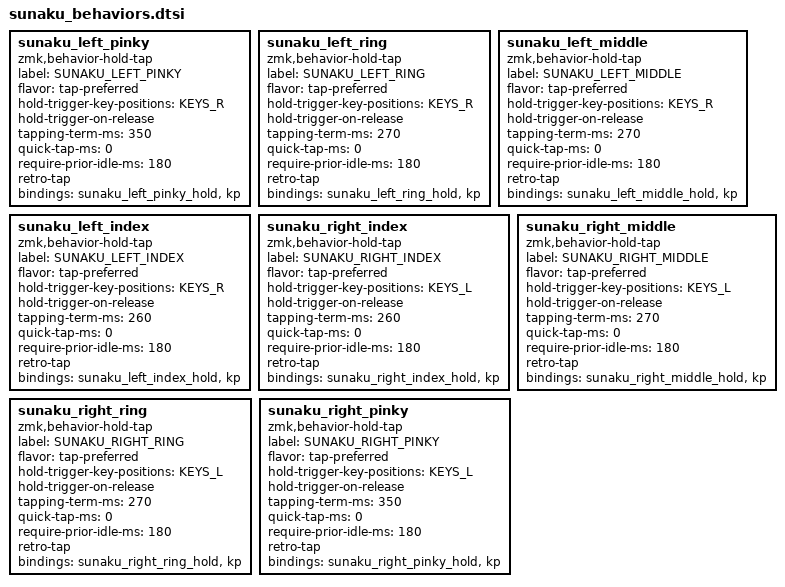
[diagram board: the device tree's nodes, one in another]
// Generated by generate_sunaku.py
        sunaku_left_pinky: sunaku_left_pinky {
            compatible = "zmk,behavior-hold-tap";
            label = "SUNAKU_LEFT_PINKY";
            flavor = "tap-preferred";
            hold-trigger-key-positions = <KEYS_R>;
            hold-trigger-on-release;
            tapping-term-ms = <350>;
            quick-tap-ms = <0>;
            require-prior-idle-ms = <180>;
            #binding-cells = <2>;
            retro-tap;
            bindings = <&sunaku_left_pinky_hold>, <&kp>;
        };

        sunaku_left_ring: sunaku_left_ring {
            compatible = "zmk,behavior-hold-tap";
            label = "SUNAKU_LEFT_RING";
            flavor = "tap-preferred";
            hold-trigger-key-positions = <KEYS_R>;
            hold-trigger-on-release;
            tapping-term-ms = <270>;
            quick-tap-ms = <0>;
            require-prior-idle-ms = <180>;
            #binding-cells = <2>;
            retro-tap;
            bindings = <&sunaku_left_ring_hold>, <&kp>;
        };

        sunaku_left_middle: sunaku_left_middle {
            compatible = "zmk,behavior-hold-tap";
            label = "SUNAKU_LEFT_MIDDLE";
            flavor = "tap-preferred";
            hold-trigger-key-positions = <KEYS_R>;
            hold-trigger-on-release;
            tapping-term-ms = <270>;
            quick-tap-ms = <0>;
            require-prior-idle-ms = <180>;
            #binding-cells = <2>;
            retro-tap;
            bindings = <&sunaku_left_middle_hold>, <&kp>;
        };

        sunaku_left_index: sunaku_left_index {
            compatible = "zmk,behavior-hold-tap";
            label = "SUNAKU_LEFT_INDEX";
            flavor = "tap-preferred";
            hold-trigger-key-positions = <KEYS_R>;
            hold-trigger-on-release;
            tapping-term-ms = <260>;
            quick-tap-ms = <0>;
            require-prior-idle-ms = <180>;
            #binding-cells = <2>;
            retro-tap;
            bindings = <&sunaku_left_index_hold>, <&kp>;
        };

        sunaku_right_index: sunaku_right_index {
            compatible = "zmk,behavior-hold-tap";
            label = "SUNAKU_RIGHT_INDEX";
            flavor = "tap-preferred";
            hold-trigger-key-positions = <KEYS_L>;
            hold-trigger-on-release;
            tapping-term-ms = <260>;
            quick-tap-ms = <0>;
            require-prior-idle-ms = <180>;
            #binding-cells = <2>;
            retro-tap;
            bindings = <&sunaku_right_index_hold>, <&kp>;
        };

        sunaku_right_middle: sunaku_right_middle {
            compatible = "zmk,behavior-hold-tap";
            label = "SUNAKU_RIGHT_MIDDLE";
            flavor = "tap-preferred";
            hold-trigger-key-positions = <KEYS_L>;
            hold-trigger-on-release;
            tapping-term-ms = <270>;
            quick-tap-ms = <0>;
            require-prior-idle-ms = <180>;
            #binding-cells = <2>;
            retro-tap;
            bindings = <&sunaku_right_middle_hold>, <&kp>;
        };

        sunaku_right_ring: sunaku_right_ring {
            compatible = "zmk,behavior-hold-tap";
            label = "SUNAKU_RIGHT_RING";
            flavor = "tap-preferred";
            hold-trigger-key-positions = <KEYS_L>;
            hold-trigger-on-release;
            tapping-term-ms = <270>;
            quick-tap-ms = <0>;
            require-prior-idle-ms = <180>;
            #binding-cells = <2>;
            retro-tap;
            bindings = <&sunaku_right_ring_hold>, <&kp>;
        };

        sunaku_right_pinky: sunaku_right_pinky {
            compatible = "zmk,behavior-hold-tap";
            label = "SUNAKU_RIGHT_PINKY";
            flavor = "tap-preferred";
            hold-trigger-key-positions = <KEYS_L>;
            hold-trigger-on-release;
            tapping-term-ms = <350>;
            quick-tap-ms = <0>;
            require-prior-idle-ms = <180>;
            #binding-cells = <2>;
            retro-tap;
            bindings = <&sunaku_right_pinky_hold>, <&kp>;
        };

